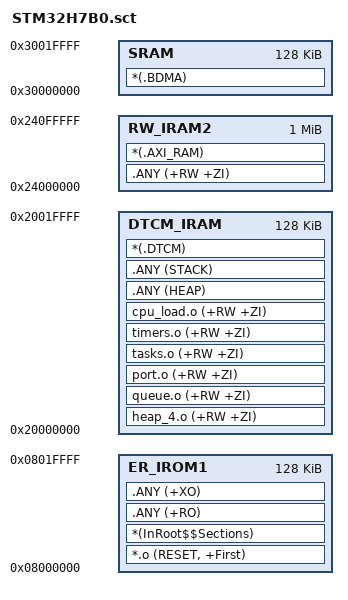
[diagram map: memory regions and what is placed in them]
; *************************************************************
; *** Scatter-Loading Description File generated by uVision ***
; *************************************************************

LR_IROM1 0x08000000 0x00020000  {    ; load region size_region
  ER_IROM1 0x08000000 0x00020000  {  ; load address = execution address
   *.o (RESET, +First)
   *(InRoot$$Sections)
   .ANY (+RO)
   .ANY (+XO)
  }
  
  DTCM_IRAM 0x20000000 0x00020000  {  ; RW data
	heap_4.o (+RW +ZI)
	queue.o (+RW +ZI)
	port.o (+RW +ZI)
	tasks.o (+RW +ZI)
	timers.o (+RW +ZI)
	cpu_load.o (+RW +ZI)
	.ANY (HEAP)
    .ANY (STACK)
   *(.DTCM)
  }
  RW_IRAM2 0x24000000 0x00100000  {		; AXI RAM 
   .ANY (+RW +ZI)
   *(.AXI_RAM)
  }
  SRAM 0x30000000  0x00020000  {  ; RW data
  *(.BDMA)						; BDMA access
  }

}

